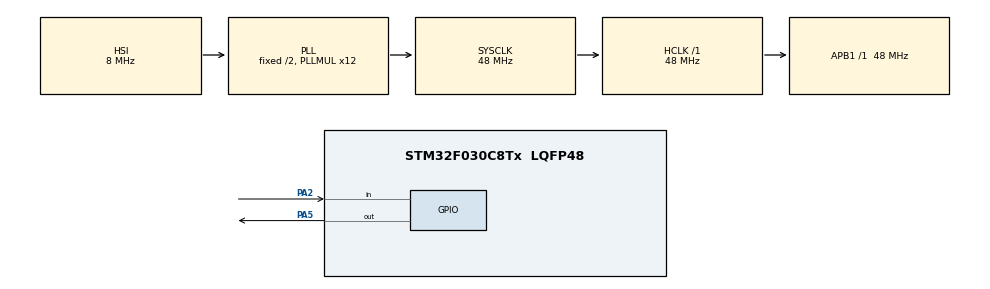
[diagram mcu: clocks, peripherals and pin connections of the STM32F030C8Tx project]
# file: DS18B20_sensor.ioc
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FREERTOS.Tasks01=Task1,0,128,StartTask1,Default,NULL,Dynamic,NULL,NULL
Mcu.Family=STM32F0
Mcu.Name=STM32F030C8Tx
Mcu.Package=LQFP48
NVIC.TIM3_IRQn=true\:3\:0\:false\:false\:true\:false\:false\:true\:true
NVIC.TimeBase=TIM3_IRQn
NVIC.TimeBaseIP=TIM3
PA2.Signal=GPIO_Input
PA5.Signal=GPIO_Output
ProjectManager.HeapSize=0x200
ProjectManager.StackSize=0x400
ProjectManager.TargetToolchain=STM32CubeIDE
RCC.AHBFreq_Value=48000000
RCC.APB1Freq_Value=48000000
RCC.APB1TimFreq_Value=48000000
RCC.HCLKFreq_Value=48000000
RCC.PLLMUL=RCC_PLL_MUL12
RCC.SYSCLKFreq_VALUE=48000000
RCC.SYSCLKSource=RCC_SYSCLKSOURCE_PLLCLK
TIM6.Period=0xffff
TIM6.Prescaler=47
VP_FREERTOS_VS_CMSIS_V1.Mode=CMSIS_V1
VP_SYS_VS_tim3.Mode=TIM3
VP_TIM6_VS_ClockSourceINT.Mode=Enable_Timer
board=custom

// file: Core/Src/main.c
/* USER CODE BEGIN Header */
/**
  ******************************************************************************
  * @file           : main.c
  * @brief          : Main program body
  ******************************************************************************
  * @attention
  *
  * Copyright (c) 2025 STMicroelectronics.
  * All rights reserved.
  *
  * This software is licensed under terms that can be found in the LICENSE file
  * in the root directory of this software component.
  * If no LICENSE file comes with this software, it is provided AS-IS.
  *
  ******************************************************************************
  */
/* USER CODE END Header */
#include "main.h"
#include "cmsis_os.h"
#include "tim.h"
#include "gpio.h"

/* USER CODE BEGIN Includes */

#include "ds18b20.h"
#include "onewire.h"
#include "ds18b20Config.h"

/* USER CODE END Includes */

/* USER CODE BEGIN PTD */

osThreadId TempTaskHandle;
/* USER CODE END PTD */

/* USER CODE BEGIN PD */
#define LED_TEMP GPIO_PIN_5
#define LED_PORT GPIOA
/* USER CODE END PD */

/* USER CODE BEGIN PV */

float temperature = 0;

/* USER CODE END PV */

void SystemClock_Config(void);
void MX_FREERTOS_Init(void);
/* USER CODE BEGIN PFP */

void TempTask(const void *argument);

/* USER CODE END PFP */

int main(void)
{

  /* MCU Configuration--------------------------------------------------------*/

  /* Reset of all peripherals, Initializes the Flash interface and the Systick. */
  HAL_Init();

  /* Configure the system clock */
  SystemClock_Config();

  /* Initialize all configured peripherals */
  MX_GPIO_Init();
  MX_TIM6_Init();

  /* Call init function for freertos objects (in cmsis_os2.c) */
  MX_FREERTOS_Init();

  /* Start scheduler */
  osKernelStart();

  /* We should never get here as control is now taken by the scheduler */

  /* Infinite loop */
  /* USER CODE BEGIN WHILE */
#if (_DS18B20_USE_FREERTOS==1)
    Ds18b20_Init(osPriorityNormal);
#else
    if(!Ds18b20_Init())
        Error_Handler();
#endif

    osThreadDef(TempTaskDef, TempTask, osPriorityNormal, 0, 256);
    TempTaskHandle = osThreadCreate(osThread(TempTaskDef), NULL);

    osKernelStart();

  while (1)
  {
    /* USER CODE END WHILE */

  }
}

void SystemClock_Config(void)
{
  RCC_OscInitTypeDef RCC_OscInitStruct = {0};
  RCC_ClkInitTypeDef RCC_ClkInitStruct = {0};

  /** Initializes the RCC Oscillators according to the specified parameters
  * in the RCC_OscInitTypeDef structure.
  */
  RCC_OscInitStruct.OscillatorType = RCC_OSCILLATORTYPE_HSI;
  RCC_OscInitStruct.HSIState = RCC_HSI_ON;
  RCC_OscInitStruct.HSICalibrationValue = RCC_HSICALIBRATION_DEFAULT;
  RCC_OscInitStruct.PLL.PLLState = RCC_PLL_ON;
  RCC_OscInitStruct.PLL.PLLSource = RCC_PLLSOURCE_HSI;
  RCC_OscInitStruct.PLL.PLLMUL = RCC_PLL_MUL12;
  RCC_OscInitStruct.PLL.PREDIV = RCC_PREDIV_DIV1;
  if (HAL_RCC_OscConfig(&RCC_OscInitStruct) != HAL_OK)
  {
    Error_Handler();
  }

  /** Initializes the CPU, AHB and APB buses clocks
  */
  RCC_ClkInitStruct.ClockType = RCC_CLOCKTYPE_HCLK|RCC_CLOCKTYPE_SYSCLK
                              |RCC_CLOCKTYPE_PCLK1;
  RCC_ClkInitStruct.SYSCLKSource = RCC_SYSCLKSOURCE_PLLCLK;
  RCC_ClkInitStruct.AHBCLKDivider = RCC_SYSCLK_DIV1;
  RCC_ClkInitStruct.APB1CLKDivider = RCC_HCLK_DIV1;

  if (HAL_RCC_ClockConfig(&RCC_ClkInitStruct, FLASH_LATENCY_1) != HAL_OK)
  {
    Error_Handler();
  }
}

/* USER CODE BEGIN 4 */

void TempTask(const void *argument)  // <-- const void* ekledik
{
    (void)argument; // kullanılmıyor ama derleyici uyarısı için
    while(1)
    {
        for(uint8_t i=0; i<_DS18B20_MAX_SENSORS; i++)
        {
            if(ds18b20[i].DataIsValid)
            {
                float temp = ds18b20[i].Temperature;

                if(temp > 30.0f)
                    HAL_GPIO_WritePin(LED_PORT, LED_TEMP, GPIO_PIN_SET);
                else
                    HAL_GPIO_WritePin(LED_PORT, LED_TEMP, GPIO_PIN_RESET);
            }
        }
        osDelay(1000);
    }
}

/* USER CODE END 4 */

void HAL_TIM_PeriodElapsedCallback(TIM_HandleTypeDef *htim)
{
  if (htim->Instance == TIM3)
  {
    HAL_IncTick();
  }
}

void Error_Handler(void)
{
  __disable_irq();
  while (1)
  {
  }
}

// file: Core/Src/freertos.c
/* USER CODE BEGIN Header */
/**
  ******************************************************************************
  * File Name          : freertos.c
  * Description        : Code for freertos applications
  ******************************************************************************
  * @attention
  *
  * Copyright (c) 2025 STMicroelectronics.
  * All rights reserved.
  *
  * This software is licensed under terms that can be found in the LICENSE file
  * in the root directory of this software component.
  * If no LICENSE file comes with this software, it is provided AS-IS.
  *
  ******************************************************************************
  */
/* USER CODE END Header */

#include "FreeRTOS.h"
#include "task.h"
#include "main.h"
#include "cmsis_os.h"

osThreadId Task1Handle;

void StartTask1(void const * argument);

void MX_FREERTOS_Init(void); /* (MISRA C 2004 rule 8.1) */

/* GetIdleTaskMemory prototype (linked to static allocation support) */
void vApplicationGetIdleTaskMemory( StaticTask_t **ppxIdleTaskTCBBuffer, StackType_t **ppxIdleTaskStackBuffer, uint32_t *pulIdleTaskStackSize );

/* USER CODE BEGIN GET_IDLE_TASK_MEMORY */
static StaticTask_t xIdleTaskTCBBuffer;
static StackType_t xIdleStack[configMINIMAL_STACK_SIZE];

void vApplicationGetIdleTaskMemory( StaticTask_t **ppxIdleTaskTCBBuffer, StackType_t **ppxIdleTaskStackBuffer, uint32_t *pulIdleTaskStackSize )
{
  *ppxIdleTaskTCBBuffer = &xIdleTaskTCBBuffer;
  *ppxIdleTaskStackBuffer = &xIdleStack[0];
  *pulIdleTaskStackSize = configMINIMAL_STACK_SIZE;
  /* place for user code */
}
/* USER CODE END GET_IDLE_TASK_MEMORY */

void MX_FREERTOS_Init(void) {

  /* Create the thread(s) */
  /* definition and creation of Task1 */
  osThreadDef(Task1, StartTask1, osPriorityNormal, 0, 128);
  Task1Handle = osThreadCreate(osThread(Task1), NULL);

}

void StartTask1(void const * argument)
{
  for(;;)
  {
    osDelay(1);
  }
}
